# USB_USB2SS_EXTCAP_31000960h register map
Vendor: Texas Instruments
Peripheral module from a debugger description file (folder am62D).
Registers are 32-bit, access per field, reset 0x401 unless marked. A register's access mark holds for its fields unless they carry their own. Offsets are as the file gives them; lines under a group give offsets from that group; [hi:lo] are bit positions; {n}, {i} and the like mark numbered series; 'fields as' and 'values as' point back to an identical list; <NAME> marks a mode.

## USB2SS_EXTCAP
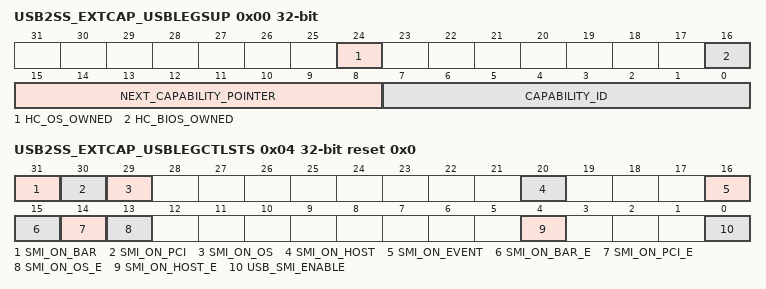
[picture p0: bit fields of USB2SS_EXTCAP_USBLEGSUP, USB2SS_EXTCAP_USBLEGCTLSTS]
0x00 USB2SS_EXTCAP_USBLEGSUP — USBLEGSUP
  [24] HC_OS_OWNED rw — HC_OS_OWNED SEMAPHOREFor a description of this standard USB register field, see the eXtensible Host Controller Interface for Universal Serial Bus [USB] Specification 3.0. Reset Source: rst_mod_g_rst_n
  [16] HC_BIOS_OWNED rw — HC_BIOS_OWNED SEMAPHOREFor a description of this standard USB register field, see the eXtensible Host Controller Interface for Universal Serial Bus [USB] Specification 3.0. Reset Source: rst_mod_g_rst_n
  [15:8] NEXT_CAPABILITY_POINTER ro — NEXT_CAPABILITY_POINTERFor a description of this standard USB register field, see the eXtensible Host Controller Interface for Universal Serial Bus [USB] Specification 3.0. Reset Source: rst_mod_g_rst_n
  [7:0] CAPABILITY_ID ro — CAPABILITY_IDset_register_field_attribute DWC_usb3_map/DWC_usb3_block_HC_Extended_Capability_Register/USBLEGSUP/CAPABILITY_ID RegisterResetValue 0x1For a description of this standard USB register field, see the eXtensible Host Controller Interface for Universal Serial Bus [USB] Specification 3.0. Reset Source: rst_mod_g_rst_n
0x04 USB2SS_EXTCAP_USBLEGCTLSTS access not given reset 0x0 — USBLEGCTLSTS
  [31] SMI_ON_BAR — SMI_ON_BARFor a description of this standard USB register field, see the eXtensible Host Controller Interface for Universal Serial Bus [USB] Specification 3.0. Reset Source: rst_mod_g_rst_n (access R/W1TC)
  [30] SMI_ON_PCI — SMI_ON_PCI COMMANDFor a description of this standard USB register field, see the eXtensible Host Controller Interface for Universal Serial Bus [USB] Specification 3.0. Reset Source: rst_mod_g_rst_n (access R/W1TC)
  [29] SMI_ON_OS — SMI_ON_OS OWNERSHIP CHANGEFor a description of this standard USB register field, see the eXtensible Host Controller Interface for Universal Serial Bus [USB] Specification 3.0. Reset Source: rst_mod_g_rst_n (access R/W1TC)
  [20] SMI_ON_HOST ro — SMI_ON_HOST SYSTEM ERRORFor a description of this standard USB register field, see the eXtensible Host Controller Interface for Universal Serial Bus [USB] Specification 3.0. Reset Source: rst_mod_g_rst_n
  [16] SMI_ON_EVENT ro — SMI_ON_EVENT INTERRUPTFor a description of this standard USB register field, see the eXtensible Host Controller Interface for Universal Serial Bus [USB] Specification 3.0. Reset Source: rst_mod_g_rst_n
  [15] SMI_ON_BAR_E rw — SMI_ON_BAR ENABLEFor a description of this standard USB register field, see the eXtensible Host Controller Interface for Universal Serial Bus [USB] Specification 3.0. Reset Source: rst_mod_g_rst_n
  [14] SMI_ON_PCI_E rw — SMI_ON_PCI COMMAND ENABLEFor a description of this standard USB register field, see the eXtensible Host Controller Interface for Universal Serial Bus [USB] Specification 3.0. Reset Source: rst_mod_g_rst_n
  [13] SMI_ON_OS_E rw — SMI_ON_OS OWNERSHIP ENABLEFor a description of this standard USB register field, see the eXtensible Host Controller Interface for Universal Serial Bus [USB] Specification 3.0. Reset Source: rst_mod_g_rst_n
  [4] SMI_ON_HOST_E rw — SMI_ON_HOST SYSTEM ERROR ENABLEFor a description of this standard USB register field, see the eXtensible Host Controller Interface for Universal Serial Bus [USB] Specification 3.0. Reset Source: rst_mod_g_rst_n
  [0] USB_SMI_ENABLE rw — USB_SMI_ENABLEFor a description of this standard USB register field, see the eXtensible Host Controller Interface for Universal Serial Bus [USB] Specification 3.0. Reset Source: rst_mod_g_rst_n
